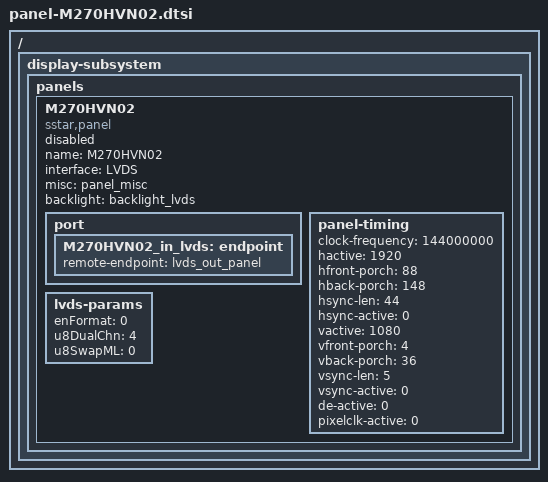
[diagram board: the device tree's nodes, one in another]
/*
* M270HVN02-panel.dtsi- Sigmastar
*
* Copyright (c) [2019~2020] SigmaStar Technology.
*
*
* This software is licensed under the terms of the GNU General Public
* License version 2, as published by the Free Software Foundation, and
* may be copied, distributed, and modified under those terms.
*
* This program is distributed in the hope that it will be useful,
* but WITHOUT ANY WARRANTY; without even the implied warranty of
* MERCHANTABILITY or FITNESS FOR A PARTICULAR PURPOSE.  See the
* GNU General Public License version 2 for more details.
*
*/

/ {
    display-subsystem {
        panels {
            M270HVN02 {
                compatible = "sstar,panel";
                name = "M270HVN02";
                interface = "LVDS"; /* TTL/MIPI/LVDS/BT1120/BT656 */
                misc = <&panel_misc>;
                backlight = <&backlight_lvds>;
                status = "disable";

                port {
                    M270HVN02_in_lvds: endpoint {
                        remote-endpoint = <&lvds_out_panel>;
                    };
                };

                panel-timing {
                    clock-frequency = <144000000>;
                    hactive = <1920>;
                    hfront-porch = <88>;
                    hback-porch = <148>;
                    hsync-len = <44>;
                    hsync-active = <0>;
                    vactive = <1080>;
                    vfront-porch = <4>;
                    vback-porch = <36>;
                    vsync-len = <5>;
                    vsync-active = <0>;
                    de-active = <0>;
                    pixelclk-active = <0>;
                };
                lvds-params {
                    enFormat = <0>;
                    u8DualChn = <4>;
                    u8SwapML = <0>;
                };
            };
        };
    };
};
